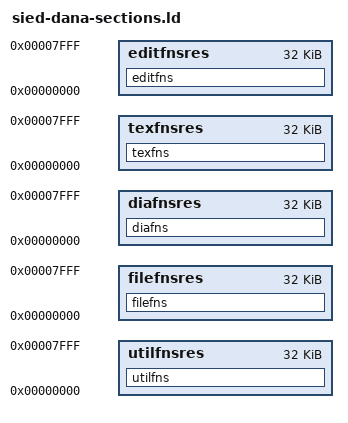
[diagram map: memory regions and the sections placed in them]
/* DO NOT EDIT!
   This file was automatically generated by m68k-palmos-multigen v2.3
   from ../resources/sied-dana.def  */

MEMORY
{
	utilfnsres : ORIGIN = 0x0, LENGTH = 32768
	filefnsres : ORIGIN = 0x0, LENGTH = 32768
	diafnsres : ORIGIN = 0x0, LENGTH = 32768
	texfnsres : ORIGIN = 0x0, LENGTH = 32768
	editfnsres : ORIGIN = 0x0, LENGTH = 32768
}

SECTIONS
{
	utilfns : { *(utilfns) } > utilfnsres
	filefns : { *(filefns) } > filefnsres
	diafns : { *(diafns) } > diafnsres
	texfns : { *(texfns) } > texfnsres
	editfns : { *(editfns) } > editfnsres
}
